# CY8C5888LTI_LP097 register map
File version: 0.1
CY8C58LP
Registers are 8-bit, read-write, no defined reset value unless marked. A register's access mark holds for its fields unless they carry their own. Offsets are from the block's base; lines under a group give offsets from that group; [hi:lo] are bit positions; {n}, {i} and the like mark numbered series; 'fields as' and 'values as' point back to an identical list; <NAME> marks a mode.

## Memory map
0x00000000 SleepTimer

## SleepTimer
Base 0x00000000
0x40004381 SleepTimer_CTW_INTERVAL_REG — Timewheel Configuration Register 1
  [3:0] ctw_interval — Sets the central timewheel interval.
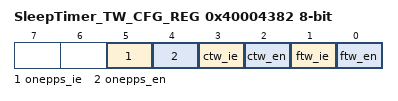
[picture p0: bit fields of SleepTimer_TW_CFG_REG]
0x40004382 SleepTimer_TW_CFG_REG — Timewheel Configuration Register 2
  [5] onepps_ie — When set and one pulse-per-second is enabled, an interrupt is issued when the pulse occurs.
    1=Enabled (One PPS interrupt is enabled); 0=Disabled (One PPS interrupt is disabled)
  [4] onepps_en — When set, the system returns to the active global power mode once every second.
    1=Enabled (One PPS is enabled); 0=Disabled (One PPS is disabled)
  [3] ctw_ie — When set and the central timewheel is enabled, an interrupt is issued when the central timewheel reaches the selected interval.
    1=Enabled (CTW interrupt is enabled); 0=Disabled (CTW interrupt is disabled)
  [2] ctw_en — When set, the system returns to the active global power mode when the central timewheel reaches the selected interval.
    1=Enabled (CTW is enabled); 0=Disabled (CTW is disabled)
  [1] ftw_ie — When set and the fast timewheel is enabled, an interrupt is issued when it reaches the terminal count.
    1=Enabled (FTW interrupt is enabled); 0=Disabled (FTW interrupt is disabled)
  [0] ftw_en — When set, the system returns to the active global power mode when the fast timewheel reaches the selected interval.
    1=Enabled (FTW is enabled); 0=Disabled (FTW is disabled)
